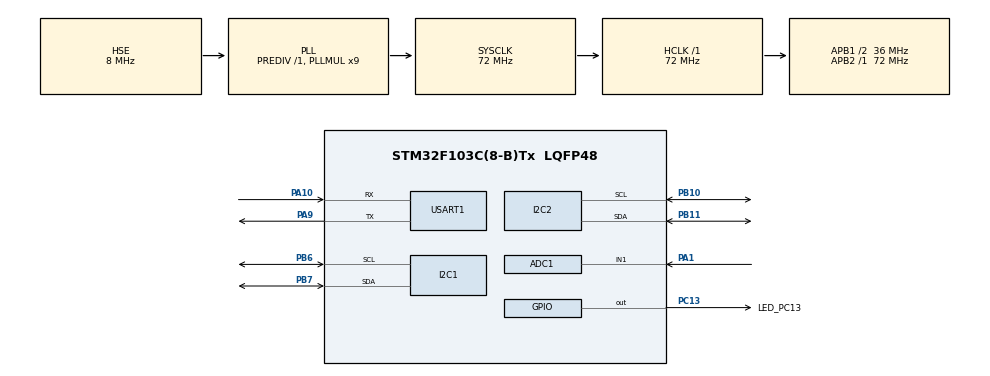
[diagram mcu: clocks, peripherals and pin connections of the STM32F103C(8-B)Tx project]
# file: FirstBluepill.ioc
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ADC1.Channel-4\#ChannelRegularConversion=ADC_CHANNEL_1
ADC1.NbrOfConversionFlag=1
ADC1.Rank-4\#ChannelRegularConversion=1
ADC1.SamplingTime-4\#ChannelRegularConversion=ADC_SAMPLETIME_1CYCLE_5
ADC1.master=1
Mcu.Family=STM32F1
Mcu.Name=STM32F103C(8-B)Tx
Mcu.Package=LQFP48
NVIC.PriorityGroup=NVIC_PRIORITYGROUP_4
PA1.Signal=ADCx_IN1
PA10.Mode=Asynchronous
PA10.Signal=USART1_RX
PA13.Mode=Serial_Wire
PA13.Signal=SYS_JTMS-SWDIO
PA14.Mode=Serial_Wire
PA14.Signal=SYS_JTCK-SWCLK
PA9.Mode=Asynchronous
PA9.Signal=USART1_TX
PB10.Mode=I2C
PB10.Signal=I2C2_SCL
PB11.Mode=I2C
PB11.Signal=I2C2_SDA
PB6.Mode=I2C
PB6.Signal=I2C1_SCL
PB7.Mode=I2C
PB7.Signal=I2C1_SDA
PC13-TAMPER-RTC.GPIO_Label=LED_PC13
PC13-TAMPER-RTC.Signal=GPIO_Output
PD0-OSC_IN.Mode=HSE-External-Oscillator
PD0-OSC_IN.Signal=RCC_OSC_IN
PD1-OSC_OUT.Mode=HSE-External-Oscillator
PD1-OSC_OUT.Signal=RCC_OSC_OUT
ProjectManager.HeapSize=0x200
ProjectManager.StackSize=0x400
ProjectManager.TargetToolchain=TrueSTUDIO
RCC.ADCPresc=RCC_ADCPCLK2_DIV6
RCC.AHBFreq_Value=72000000
RCC.APB1CLKDivider=RCC_HCLK_DIV2
RCC.APB1Freq_Value=36000000
RCC.APB1TimFreq_Value=72000000
RCC.APB2Freq_Value=72000000
RCC.APB2TimFreq_Value=72000000
RCC.HCLKFreq_Value=72000000
RCC.PLLMUL=RCC_PLL_MUL9
RCC.PLLSourceVirtual=RCC_PLLSOURCE_HSE
RCC.SYSCLKFreq_VALUE=72000000
RCC.SYSCLKSource=RCC_SYSCLKSOURCE_PLLCLK
RCC.USBFreq_Value=72000000
SH.ADCx_IN1.0=ADC1_IN1,IN1
USART1.VirtualMode=VM_ASYNC
board=custom

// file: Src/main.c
/**
  ******************************************************************************
  * @file           : main.c
  * @brief          : Main program body
  ******************************************************************************
  ** This notice applies to any and all portions of this file
  * that are not between comment pairs USER CODE BEGIN and
  * USER CODE END. Other portions of this file, whether
  * inserted by the user or by software development tools
  * are owned by their respective copyright owners.
  *
  * COPYRIGHT(c) 2019 STMicroelectronics
  *
  * Redistribution and use in source and binary forms, with or without modification,
  * are permitted provided that the following conditions are met:
  *   1. Redistributions of source code must retain the above copyright notice,
  *      this list of conditions and the following disclaimer.
  *   2. Redistributions in binary form must reproduce the above copyright notice,
  *      this list of conditions and the following disclaimer in the documentation
  *      and/or other materials provided with the distribution.
  *   3. Neither the name of STMicroelectronics nor the names of its contributors
  *      may be used to endorse or promote products derived from this software
  *      without specific prior written permission.
  *
  * THIS SOFTWARE IS PROVIDED BY THE COPYRIGHT HOLDERS AND CONTRIBUTORS "AS IS"
  * AND ANY EXPRESS OR IMPLIED WARRANTIES, INCLUDING, BUT NOT LIMITED TO, THE
  * IMPLIED WARRANTIES OF MERCHANTABILITY AND FITNESS FOR A PARTICULAR PURPOSE ARE
  * DISCLAIMED. IN NO EVENT SHALL THE COPYRIGHT HOLDER OR CONTRIBUTORS BE LIABLE
  * FOR ANY DIRECT, INDIRECT, INCIDENTAL, SPECIAL, EXEMPLARY, OR CONSEQUENTIAL
  * DAMAGES (INCLUDING, BUT NOT LIMITED TO, PROCUREMENT OF SUBSTITUTE GOODS OR
  * SERVICES; LOSS OF USE, DATA, OR PROFITS; OR BUSINESS INTERRUPTION) HOWEVER
  * CAUSED AND ON ANY THEORY OF LIABILITY, WHETHER IN CONTRACT, STRICT LIABILITY,
  * OR TORT (INCLUDING NEGLIGENCE OR OTHERWISE) ARISING IN ANY WAY OUT OF THE USE
  * OF THIS SOFTWARE, EVEN IF ADVISED OF THE POSSIBILITY OF SUCH DAMAGE.
  *
  ******************************************************************************
  */
#include "main.h"
#include "stm32f1xx_hal.h"

ADC_HandleTypeDef hadc1;

I2C_HandleTypeDef hi2c1;
I2C_HandleTypeDef hi2c2;

UART_HandleTypeDef huart1;

/* USER CODE BEGIN PV */
/* Private variables ---------------------------------------------------------*/

/* USER CODE END PV */

void SystemClock_Config(void);
static void MX_GPIO_Init(void);
static void MX_USART1_UART_Init(void);
static void MX_ADC1_Init(void);
static void MX_I2C1_Init(void);
static void MX_I2C2_Init(void);

/* USER CODE BEGIN PFP */
/* Private function prototypes -----------------------------------------------*/

/* USER CODE END PFP */

/* USER CODE BEGIN 0 */
#ifdef __GNUC__
int _write(int file, uint8_t* ptr, int len)
{
	HAL_UART_Transmit(&huart,ptr,len,1000);
	return len;
}
#elif(__ICCARM__||__CC_ARM)
int fputc(int c,FILE* stream)
{
	HAL_UART_Transmit(&huart1,(uint8_t*)&c,1,1000);
	return c;
}
#endif

int TestCount =0;
/* USER CODE END 0 */

int main(void)
{

  /* MCU Configuration----------------------------------------------------------*/

  /* Reset of all peripherals, Initializes the Flash interface and the Systick. */
  //HAL_Init();

  /* Configure the system clock */
  SystemClock_Config();

  /* Initialize all configured peripherals */
  MX_GPIO_Init();
  MX_USART1_UART_Init();
  MX_ADC1_Init();
  MX_I2C1_Init();
  MX_I2C2_Init();
  /* USER CODE BEGIN 2 */
  printf("USART_printf Test\r\n");
  /* USER CODE END 2 */

  /* Infinite loop */
  while (1)
  {

  /* USER CODE BEGIN 3 */
	  printf("USART_Main Run Test! = %d \r\n", TestCount);

	  TestCount++;

  }
  /* USER CODE END 3 */

}

void SystemClock_Config(void)
{

  RCC_OscInitTypeDef RCC_OscInitStruct;
  RCC_ClkInitTypeDef RCC_ClkInitStruct;
  RCC_PeriphCLKInitTypeDef PeriphClkInit;

    /**Initializes the CPU, AHB and APB busses clocks
    */
  RCC_OscInitStruct.OscillatorType = RCC_OSCILLATORTYPE_HSE;
  RCC_OscInitStruct.HSEState = RCC_HSE_ON;
  RCC_OscInitStruct.HSEPredivValue = RCC_HSE_PREDIV_DIV1;
  RCC_OscInitStruct.HSIState = RCC_HSI_ON;
  RCC_OscInitStruct.PLL.PLLState = RCC_PLL_ON;
  RCC_OscInitStruct.PLL.PLLSource = RCC_PLLSOURCE_HSE;
  RCC_OscInitStruct.PLL.PLLMUL = RCC_PLL_MUL9;
  if (HAL_RCC_OscConfig(&RCC_OscInitStruct) != HAL_OK)
  {
    _Error_Handler(__FILE__, __LINE__);
  }

    /**Initializes the CPU, AHB and APB busses clocks
    */
  RCC_ClkInitStruct.ClockType = RCC_CLOCKTYPE_HCLK|RCC_CLOCKTYPE_SYSCLK
                              |RCC_CLOCKTYPE_PCLK1|RCC_CLOCKTYPE_PCLK2;
  RCC_ClkInitStruct.SYSCLKSource = RCC_SYSCLKSOURCE_PLLCLK;
  RCC_ClkInitStruct.AHBCLKDivider = RCC_SYSCLK_DIV1;
  RCC_ClkInitStruct.APB1CLKDivider = RCC_HCLK_DIV2;
  RCC_ClkInitStruct.APB2CLKDivider = RCC_HCLK_DIV1;

  if (HAL_RCC_ClockConfig(&RCC_ClkInitStruct, FLASH_LATENCY_2) != HAL_OK)
  {
    _Error_Handler(__FILE__, __LINE__);
  }

  PeriphClkInit.PeriphClockSelection = RCC_PERIPHCLK_ADC;
  PeriphClkInit.AdcClockSelection = RCC_ADCPCLK2_DIV6;
  if (HAL_RCCEx_PeriphCLKConfig(&PeriphClkInit) != HAL_OK)
  {
    _Error_Handler(__FILE__, __LINE__);
  }

    /**Configure the Systick interrupt time
    */
  HAL_SYSTICK_Config(HAL_RCC_GetHCLKFreq()/1000);

    /**Configure the Systick
    */
  HAL_SYSTICK_CLKSourceConfig(SYSTICK_CLKSOURCE_HCLK);

  /* SysTick_IRQn interrupt configuration */
  HAL_NVIC_SetPriority(SysTick_IRQn, 0, 0);
}

/* ADC1 init function */
static void MX_ADC1_Init(void)
{

  ADC_ChannelConfTypeDef sConfig;

    /**Common config
    */
  hadc1.Instance = ADC1;
  hadc1.Init.ScanConvMode = ADC_SCAN_DISABLE;
  hadc1.Init.ContinuousConvMode = DISABLE;
  hadc1.Init.DiscontinuousConvMode = DISABLE;
  hadc1.Init.ExternalTrigConv = ADC_SOFTWARE_START;
  hadc1.Init.DataAlign = ADC_DATAALIGN_RIGHT;
  hadc1.Init.NbrOfConversion = 1;
  if (HAL_ADC_Init(&hadc1) != HAL_OK)
  {
    _Error_Handler(__FILE__, __LINE__);
  }

    /**Configure Regular Channel
    */
  sConfig.Channel = ADC_CHANNEL_1;
  sConfig.Rank = ADC_REGULAR_RANK_1;
  sConfig.SamplingTime = ADC_SAMPLETIME_1CYCLE_5;
  if (HAL_ADC_ConfigChannel(&hadc1, &sConfig) != HAL_OK)
  {
    _Error_Handler(__FILE__, __LINE__);
  }

}

/* I2C1 init function */
static void MX_I2C1_Init(void)
{

  hi2c1.Instance = I2C1;
  hi2c1.Init.ClockSpeed = 100000;
  hi2c1.Init.DutyCycle = I2C_DUTYCYCLE_2;
  hi2c1.Init.OwnAddress1 = 0;
  hi2c1.Init.AddressingMode = I2C_ADDRESSINGMODE_7BIT;
  hi2c1.Init.DualAddressMode = I2C_DUALADDRESS_DISABLE;
  hi2c1.Init.OwnAddress2 = 0;
  hi2c1.Init.GeneralCallMode = I2C_GENERALCALL_DISABLE;
  hi2c1.Init.NoStretchMode = I2C_NOSTRETCH_DISABLE;
  if (HAL_I2C_Init(&hi2c1) != HAL_OK)
  {
    _Error_Handler(__FILE__, __LINE__);
  }

}

/* I2C2 init function */
static void MX_I2C2_Init(void)
{

  hi2c2.Instance = I2C2;
  hi2c2.Init.ClockSpeed = 100000;
  hi2c2.Init.DutyCycle = I2C_DUTYCYCLE_2;
  hi2c2.Init.OwnAddress1 = 0;
  hi2c2.Init.AddressingMode = I2C_ADDRESSINGMODE_7BIT;
  hi2c2.Init.DualAddressMode = I2C_DUALADDRESS_DISABLE;
  hi2c2.Init.OwnAddress2 = 0;
  hi2c2.Init.GeneralCallMode = I2C_GENERALCALL_DISABLE;
  hi2c2.Init.NoStretchMode = I2C_NOSTRETCH_DISABLE;
  if (HAL_I2C_Init(&hi2c2) != HAL_OK)
  {
    _Error_Handler(__FILE__, __LINE__);
  }

}

/* USART1 init function */
static void MX_USART1_UART_Init(void)
{

  huart1.Instance = USART1;
  huart1.Init.BaudRate = 115200;
  huart1.Init.WordLength = UART_WORDLENGTH_8B;
  huart1.Init.StopBits = UART_STOPBITS_1;
  huart1.Init.Parity = UART_PARITY_NONE;
  huart1.Init.Mode = UART_MODE_TX_RX;
  huart1.Init.HwFlowCtl = UART_HWCONTROL_NONE;
  huart1.Init.OverSampling = UART_OVERSAMPLING_16;
  if (HAL_UART_Init(&huart1) != HAL_OK)
  {
    _Error_Handler(__FILE__, __LINE__);
  }

}

/** Configure pins as
        * Analog
        * Input
        * Output
        * EVENT_OUT
        * EXTI
*/
static void MX_GPIO_Init(void)
{

  GPIO_InitTypeDef GPIO_InitStruct;

  /* GPIO Ports Clock Enable */
  __HAL_RCC_GPIOC_CLK_ENABLE();
  __HAL_RCC_GPIOD_CLK_ENABLE();
  __HAL_RCC_GPIOA_CLK_ENABLE();
  __HAL_RCC_GPIOB_CLK_ENABLE();

  /*Configure GPIO pin Output Level */
  HAL_GPIO_WritePin(LED_PC13_GPIO_Port, LED_PC13_Pin, GPIO_PIN_RESET);

  /*Configure GPIO pin : LED_PC13_Pin */
  GPIO_InitStruct.Pin = LED_PC13_Pin;
  GPIO_InitStruct.Mode = GPIO_MODE_OUTPUT_PP;
  GPIO_InitStruct.Pull = GPIO_NOPULL;
  GPIO_InitStruct.Speed = GPIO_SPEED_FREQ_LOW;
  HAL_GPIO_Init(LED_PC13_GPIO_Port, &GPIO_InitStruct);

}

void _Error_Handler(char *file, int line)
{
  while(1)
  {
  }
}

/************************ (C) COPYRIGHT STMicroelectronics *****END OF FILE****/
